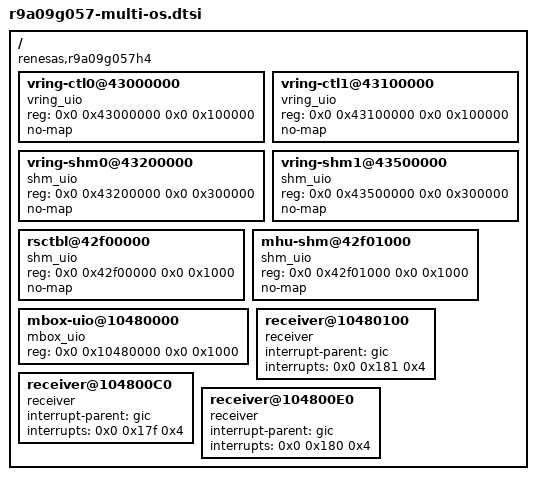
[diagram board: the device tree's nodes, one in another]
// SPDX-License-Identifier: (GPL-2.0-only OR BSD-2-Clause)
/*
 * Device Tree Source for OpenAMP-related support on the RZ/V2H SoC.
 *
 * Copyright (C) 2026 Renesas Electronics Corp.
 */

/ {
	compatible = "renesas,r9a09g057h4", "renesas,r9a09g057";

	/* ---------------------------------------------------------------- */
	/* UIO vring/shm nodes                                              */
	/* ---------------------------------------------------------------- */

	/*
	 * Shared by CM33, CR8 core0 and CR8 core1 (channel 0 + channel 1): the
	 * FSP firmware and the userspace OpenAMP agent use this single window.
	 */
	vring-ctl0@43000000 {
		compatible = "vring_uio";
		reg = <0x0 0x43000000 0x0 0x100000>;
		no-map;
	};

	vring-ctl1@43100000 {
		compatible = "vring_uio";
		reg = <0x0 0x43100000 0x0 0x100000>;
		no-map;
	};

	vring-shm0@43200000 {
		compatible = "shm_uio";
		reg = <0x0 0x43200000 0x0 0x300000>;
		no-map;
	};

	vring-shm1@43500000 {
		compatible = "shm_uio";
		reg = <0x0 0x43500000 0x0 0x300000>;
		no-map;
	};

	/* ---------------------------------------------------------------- */
	/* Resource table                                                   */
	/* ---------------------------------------------------------------- */

	rsctbl@42f00000 {
		compatible = "shm_uio";
		reg = <0x0 0x42f00000 0x0 0x1000>;
		no-map;
	};

	/* ---------------------------------------------------------------- */
	/* MHU shared-memory / mailbox / receivers                          */
	/* ---------------------------------------------------------------- */

	mhu-shm@42f01000 {
		compatible = "shm_uio";
		reg = <0x0 0x42f01000 0x0 0x1000>;
		no-map;
	};

	mbox-uio@10480000 {
		compatible = "mbox_uio";
		reg = <0x0 0x10480000 0x0 0x1000>;
		status = "okay";
	};

	receiver@10480100 {
		compatible = "receiver";
		interrupt-parent = <&gic>;
		interrupts = <0x0 0x181 0x4>;
		status = "okay";
	};

	receiver@104800C0 {
		compatible = "receiver";
		interrupt-parent = <&gic>;
		interrupts = <0x0 0x17f 0x4>;
		status = "okay";
	};

	receiver@104800E0 {
		compatible = "receiver";
		interrupt-parent = <&gic>;
		interrupts = <0x0 0x180 0x4>;
		status = "okay";
	};
};
